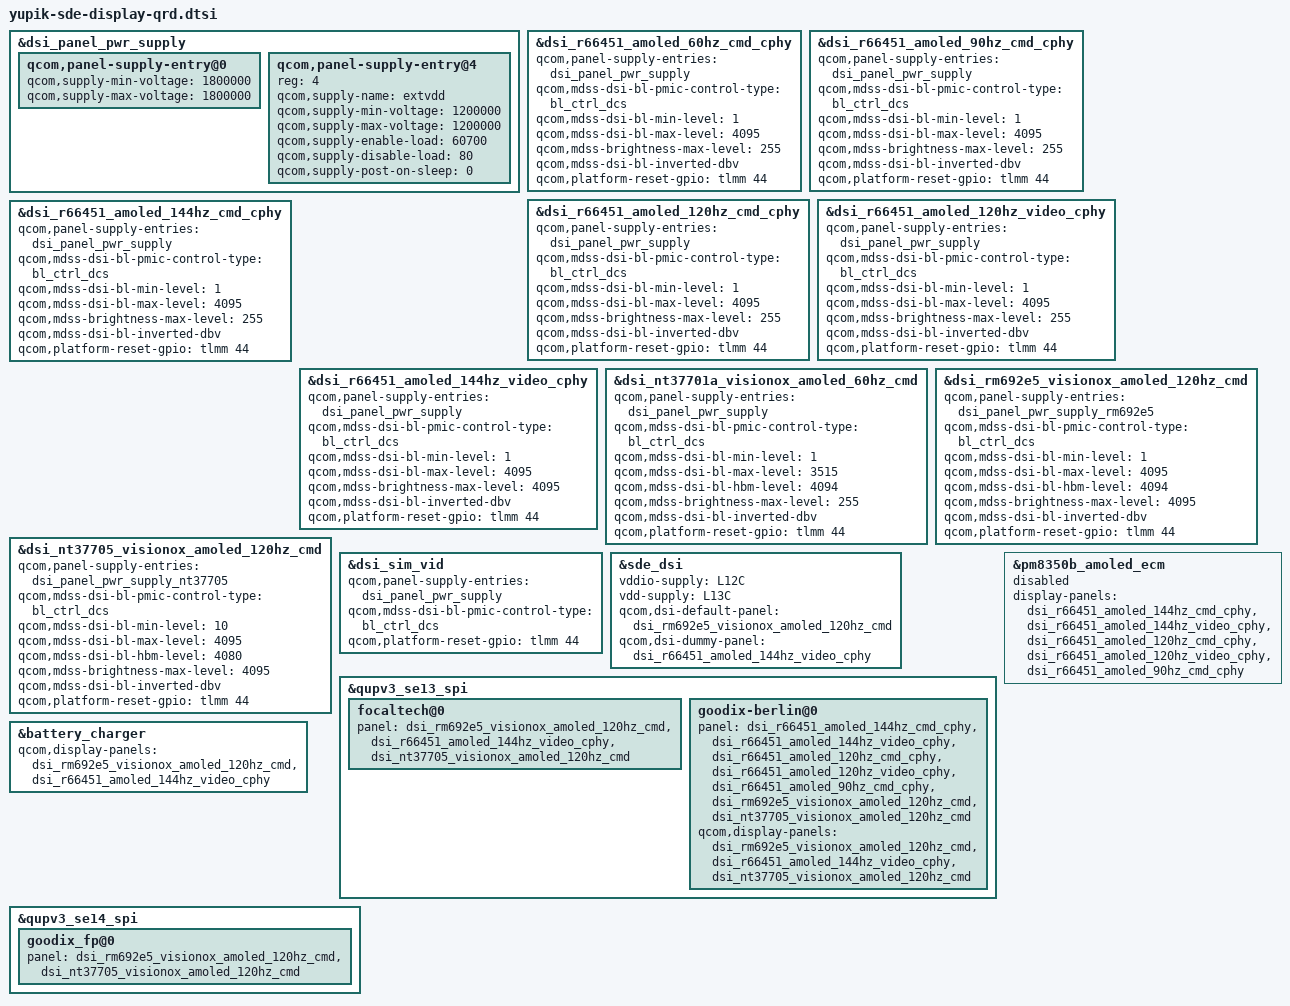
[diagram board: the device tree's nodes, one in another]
#include "yupik-sde-display.dtsi"

&dsi_panel_pwr_supply {
	qcom,panel-supply-entry@0 {
		qcom,supply-min-voltage = <1800000>;
		qcom,supply-max-voltage = <1800000>;
	};
	qcom,panel-supply-entry@4 {
		reg = <4>;
		qcom,supply-name = "extvdd";
		qcom,supply-min-voltage = <1200000>;
		qcom,supply-max-voltage = <1200000>;
		qcom,supply-enable-load = <60700>;
		qcom,supply-disable-load = <80>;
		qcom,supply-post-on-sleep = <0>;
	};
};

&dsi_r66451_amoled_60hz_cmd_cphy {
	qcom,panel-supply-entries = <&dsi_panel_pwr_supply>;
	qcom,mdss-dsi-bl-pmic-control-type = "bl_ctrl_dcs";
	qcom,mdss-dsi-bl-min-level = <1>;
	qcom,mdss-dsi-bl-max-level = <4095>;
	qcom,mdss-brightness-max-level = <255>;
	qcom,mdss-dsi-bl-inverted-dbv;
	qcom,platform-reset-gpio = <&tlmm 44 0>;
};

&dsi_r66451_amoled_90hz_cmd_cphy {
	qcom,panel-supply-entries = <&dsi_panel_pwr_supply>;
	qcom,mdss-dsi-bl-pmic-control-type = "bl_ctrl_dcs";
	qcom,mdss-dsi-bl-min-level = <1>;
	qcom,mdss-dsi-bl-max-level = <4095>;
	qcom,mdss-brightness-max-level = <255>;
	qcom,mdss-dsi-bl-inverted-dbv;
	qcom,platform-reset-gpio = <&tlmm 44 0>;
};

&dsi_r66451_amoled_120hz_cmd_cphy {
	qcom,panel-supply-entries = <&dsi_panel_pwr_supply>;
	qcom,mdss-dsi-bl-pmic-control-type = "bl_ctrl_dcs";
	qcom,mdss-dsi-bl-min-level = <1>;
	qcom,mdss-dsi-bl-max-level = <4095>;
	qcom,mdss-brightness-max-level = <255>;
	qcom,mdss-dsi-bl-inverted-dbv;
	qcom,platform-reset-gpio = <&tlmm 44 0>;
};

&dsi_r66451_amoled_120hz_video_cphy {
	qcom,panel-supply-entries = <&dsi_panel_pwr_supply>;
	qcom,mdss-dsi-bl-pmic-control-type = "bl_ctrl_dcs";
	qcom,mdss-dsi-bl-min-level = <1>;
	qcom,mdss-dsi-bl-max-level = <4095>;
	qcom,mdss-brightness-max-level = <255>;
	qcom,mdss-dsi-bl-inverted-dbv;
	qcom,platform-reset-gpio = <&tlmm 44 0>;
};

&dsi_r66451_amoled_144hz_cmd_cphy {
	qcom,panel-supply-entries = <&dsi_panel_pwr_supply>;
	qcom,mdss-dsi-bl-pmic-control-type = "bl_ctrl_dcs";
	qcom,mdss-dsi-bl-min-level = <1>;
	qcom,mdss-dsi-bl-max-level = <4095>;
	qcom,mdss-brightness-max-level = <255>;
	qcom,mdss-dsi-bl-inverted-dbv;
	qcom,platform-reset-gpio = <&tlmm 44 0>;
};

&dsi_r66451_amoled_144hz_video_cphy {
	qcom,panel-supply-entries = <&dsi_panel_pwr_supply>;
	qcom,mdss-dsi-bl-pmic-control-type = "bl_ctrl_dcs";
	qcom,mdss-dsi-bl-min-level = <1>;
	qcom,mdss-dsi-bl-max-level = <4095>;
	qcom,mdss-brightness-max-level = <4095>;
	qcom,mdss-dsi-bl-inverted-dbv;
	qcom,platform-reset-gpio = <&tlmm 44 0>;
};

&dsi_nt37701a_visionox_amoled_60hz_cmd {
	qcom,panel-supply-entries = <&dsi_panel_pwr_supply>;
	qcom,mdss-dsi-bl-pmic-control-type = "bl_ctrl_dcs";
	qcom,mdss-dsi-bl-min-level = <1>;
	qcom,mdss-dsi-bl-max-level = <3515>;
	qcom,mdss-dsi-bl-hbm-level = <4094>;
	qcom,mdss-brightness-max-level = <255>;
	qcom,mdss-dsi-bl-inverted-dbv;
	qcom,platform-reset-gpio = <&tlmm 44 0>;
};

&dsi_rm692e5_visionox_amoled_120hz_cmd {
	qcom,panel-supply-entries = <&dsi_panel_pwr_supply_rm692e5>;
	qcom,mdss-dsi-bl-pmic-control-type = "bl_ctrl_dcs";
	qcom,mdss-dsi-bl-min-level = <1>;
	qcom,mdss-dsi-bl-max-level = <4095>;
	qcom,mdss-dsi-bl-hbm-level = <4094>;
	qcom,mdss-brightness-max-level = <4095>;
	qcom,mdss-dsi-bl-inverted-dbv;
	qcom,platform-reset-gpio = <&tlmm 44 0>;
};

&dsi_nt37705_visionox_amoled_120hz_cmd {
	qcom,panel-supply-entries = <&dsi_panel_pwr_supply_nt37705>;
	qcom,mdss-dsi-bl-pmic-control-type = "bl_ctrl_dcs";
	qcom,mdss-dsi-bl-min-level = <10>;
	qcom,mdss-dsi-bl-max-level = <4095>;
	qcom,mdss-dsi-bl-hbm-level = <4080>;
	qcom,mdss-brightness-max-level = <4095>;
	qcom,mdss-dsi-bl-inverted-dbv;
	qcom,platform-reset-gpio = <&tlmm 44 0>;
};

&dsi_sim_vid {
	qcom,panel-supply-entries = <&dsi_panel_pwr_supply>;
	qcom,mdss-dsi-bl-pmic-control-type = "bl_ctrl_dcs";
	qcom,platform-reset-gpio = <&tlmm 44 0>;
};

&sde_dsi {
	vddio-supply = <&L12C>;
	vdd-supply = <&L13C>;
	/delete-property/ lab-supply;
	/delete-property/ ibb-supply;
	qcom,dsi-default-panel = <&dsi_rm692e5_visionox_amoled_120hz_cmd>;
	qcom,dsi-dummy-panel = <&dsi_r66451_amoled_144hz_video_cphy>;
};

&qupv3_se13_spi {
	focaltech@0 {
		panel = <&dsi_rm692e5_visionox_amoled_120hz_cmd
			&dsi_r66451_amoled_144hz_video_cphy
			&dsi_nt37705_visionox_amoled_120hz_cmd>;
	};

	goodix-berlin@0 {
		panel = <&dsi_r66451_amoled_144hz_cmd_cphy
			&dsi_r66451_amoled_144hz_video_cphy
			&dsi_r66451_amoled_120hz_cmd_cphy
			&dsi_r66451_amoled_120hz_video_cphy
			&dsi_r66451_amoled_90hz_cmd_cphy
			&dsi_rm692e5_visionox_amoled_120hz_cmd
			&dsi_nt37705_visionox_amoled_120hz_cmd>;
		qcom,display-panels = <&dsi_rm692e5_visionox_amoled_120hz_cmd
			&dsi_r66451_amoled_144hz_video_cphy
			&dsi_nt37705_visionox_amoled_120hz_cmd>;
	};
};

&pm8350b_amoled_ecm {
	status = "disabled";
	display-panels = <&dsi_r66451_amoled_144hz_cmd_cphy
			&dsi_r66451_amoled_144hz_video_cphy
			&dsi_r66451_amoled_120hz_cmd_cphy
			&dsi_r66451_amoled_120hz_video_cphy
			&dsi_r66451_amoled_90hz_cmd_cphy>;
};

&battery_charger {
	qcom,display-panels = <&dsi_rm692e5_visionox_amoled_120hz_cmd
			&dsi_r66451_amoled_144hz_video_cphy>;
};

&qupv3_se14_spi {
	goodix_fp@0 {
		panel = <&dsi_rm692e5_visionox_amoled_120hz_cmd
			&dsi_nt37705_visionox_amoled_120hz_cmd>;
	};
};
